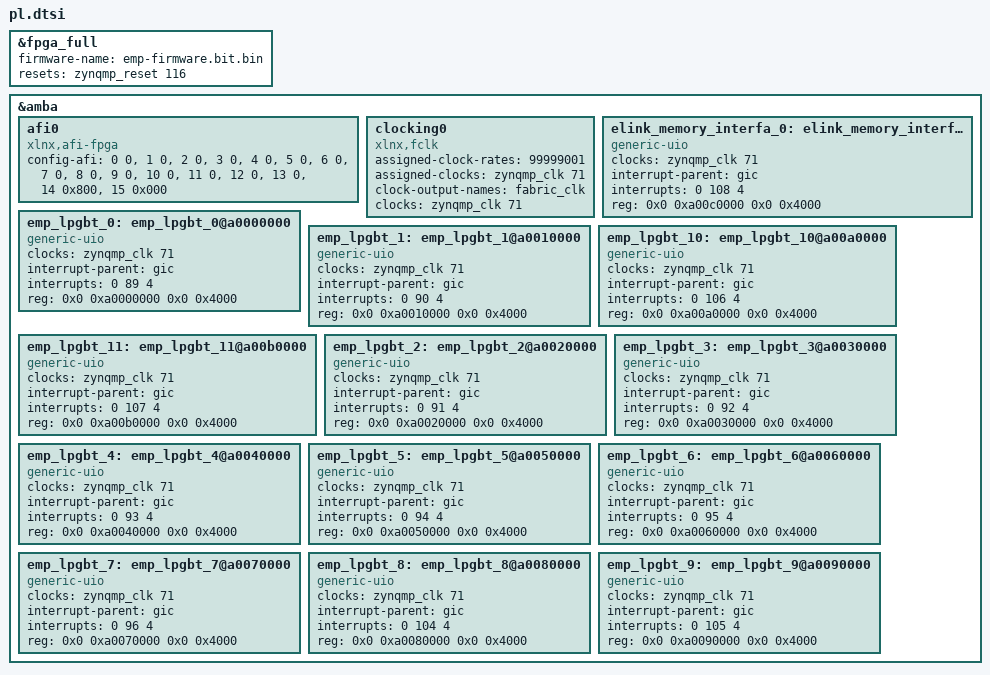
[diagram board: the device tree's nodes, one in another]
/*
 * CAUTION: This file is automatically generated by Xilinx.
 * Version:  
 * Today is: Fri Mar 19 14:35:09 2021
 */


/dts-v1/;
/plugin/;
/ {
	fragment@0 {
		target = <&fpga_full>;
		overlay0: __overlay__ {
			#address-cells = <2>;
			#size-cells = <2>;
			firmware-name = "emp-firmware.bit.bin";
			resets = <&zynqmp_reset 116>;
		};
	};
	fragment@1 {
		target = <&amba>;
		overlay1: __overlay__ {
			afi0: afi0 {
				compatible = "xlnx,afi-fpga";
				config-afi = < 0 0>, <1 0>, <2 0>, <3 0>, <4 0>, <5 0>, <6 0>, <7 0>, <8 0>, <9 0>, <10 0>, <11 0>, <12 0>, <13 0>, <14 0x800>, <15 0x000>;
			};
			clocking0: clocking0 {
				#clock-cells = <0>;
				assigned-clock-rates = <99999001>;
				assigned-clocks = <&zynqmp_clk 71>;
				clock-output-names = "fabric_clk";
				clocks = <&zynqmp_clk 71>;
				compatible = "xlnx,fclk";
			};
		};
	};
	fragment@2 {
		target = <&amba>;
		overlay2: __overlay__ {
			#address-cells = <2>;
			#size-cells = <2>;
			elink_memory_interfa_0: elink_memory_interface@a00c0000 {
				clock-names = "axi_aclk";
				clocks = <&zynqmp_clk 71>;
				compatible = "generic-uio";
				interrupt-names = "intr_done";
				interrupt-parent = <&gic>;
				interrupts = <0 108 4>;
				reg = <0x0 0xa00c0000 0x0 0x4000>;
			};
			emp_lpgbt_0: emp_lpgbt_0@a0000000 {
				clock-names = "axi_aclk";
				clocks = <&zynqmp_clk 71>;
				compatible = "generic-uio";
				interrupt-names = "int_lpgbt_resp";
				interrupt-parent = <&gic>;
				interrupts = <0 89 4>;
				reg = <0x0 0xa0000000 0x0 0x4000>;
			};
			emp_lpgbt_1: emp_lpgbt_1@a0010000 {
				clock-names = "axi_aclk";
				clocks = <&zynqmp_clk 71>;
				compatible = "generic-uio";
				interrupt-names = "int_lpgbt_resp";
				interrupt-parent = <&gic>;
				interrupts = <0 90 4>;
				reg = <0x0 0xa0010000 0x0 0x4000>;
			};
			emp_lpgbt_10: emp_lpgbt_10@a00a0000 {
				clock-names = "axi_aclk";
				clocks = <&zynqmp_clk 71>;
				compatible = "generic-uio";
				interrupt-names = "int_lpgbt_resp";
				interrupt-parent = <&gic>;
				interrupts = <0 106 4>;
				reg = <0x0 0xa00a0000 0x0 0x4000>;
			};
			emp_lpgbt_11: emp_lpgbt_11@a00b0000 {
				clock-names = "axi_aclk";
				clocks = <&zynqmp_clk 71>;
				compatible = "generic-uio";
				interrupt-names = "int_lpgbt_resp";
				interrupt-parent = <&gic>;
				interrupts = <0 107 4>;
				reg = <0x0 0xa00b0000 0x0 0x4000>;
			};
			emp_lpgbt_2: emp_lpgbt_2@a0020000 {
				clock-names = "axi_aclk";
				clocks = <&zynqmp_clk 71>;
				compatible = "generic-uio";
				interrupt-names = "int_lpgbt_resp";
				interrupt-parent = <&gic>;
				interrupts = <0 91 4>;
				reg = <0x0 0xa0020000 0x0 0x4000>;
			};
			emp_lpgbt_3: emp_lpgbt_3@a0030000 {
				clock-names = "axi_aclk";
				clocks = <&zynqmp_clk 71>;
				compatible = "generic-uio";
				interrupt-names = "int_lpgbt_resp";
				interrupt-parent = <&gic>;
				interrupts = <0 92 4>;
				reg = <0x0 0xa0030000 0x0 0x4000>;
			};
			emp_lpgbt_4: emp_lpgbt_4@a0040000 {
				clock-names = "axi_aclk";
				clocks = <&zynqmp_clk 71>;
				compatible = "generic-uio";
				interrupt-names = "int_lpgbt_resp";
				interrupt-parent = <&gic>;
				interrupts = <0 93 4>;
				reg = <0x0 0xa0040000 0x0 0x4000>;
			};
			emp_lpgbt_5: emp_lpgbt_5@a0050000 {
				clock-names = "axi_aclk";
				clocks = <&zynqmp_clk 71>;
				compatible = "generic-uio";
				interrupt-names = "int_lpgbt_resp";
				interrupt-parent = <&gic>;
				interrupts = <0 94 4>;
				reg = <0x0 0xa0050000 0x0 0x4000>;
			};
			emp_lpgbt_6: emp_lpgbt_6@a0060000 {
				clock-names = "axi_aclk";
				clocks = <&zynqmp_clk 71>;
				compatible = "generic-uio";
				interrupt-names = "int_lpgbt_resp";
				interrupt-parent = <&gic>;
				interrupts = <0 95 4>;
				reg = <0x0 0xa0060000 0x0 0x4000>;
			};
			emp_lpgbt_7: emp_lpgbt_7@a0070000 {
				clock-names = "axi_aclk";
				clocks = <&zynqmp_clk 71>;
				compatible = "generic-uio";
				interrupt-names = "int_lpgbt_resp";
				interrupt-parent = <&gic>;
				interrupts = <0 96 4>;
				reg = <0x0 0xa0070000 0x0 0x4000>;
			};
			emp_lpgbt_8: emp_lpgbt_8@a0080000 {
				clock-names = "axi_aclk";
				clocks = <&zynqmp_clk 71>;
				compatible = "generic-uio";
				interrupt-names = "int_lpgbt_resp";
				interrupt-parent = <&gic>;
				interrupts = <0 104 4>;
				reg = <0x0 0xa0080000 0x0 0x4000>;
			};
			emp_lpgbt_9: emp_lpgbt_9@a0090000 {
				clock-names = "axi_aclk";
				clocks = <&zynqmp_clk 71>;
				compatible = "generic-uio";
				interrupt-names = "int_lpgbt_resp";
				interrupt-parent = <&gic>;
				interrupts = <0 105 4>;
				reg = <0x0 0xa0090000 0x0 0x4000>;
			};
		};
	};
};
